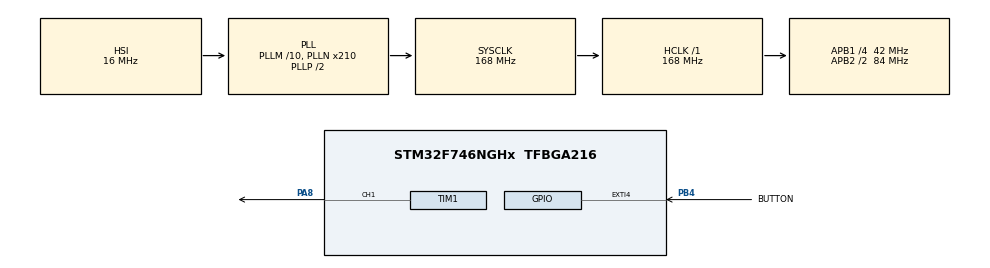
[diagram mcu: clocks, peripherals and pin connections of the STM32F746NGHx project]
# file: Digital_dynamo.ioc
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Mcu.Family=STM32F7
Mcu.Name=STM32F746NGHx
Mcu.Package=TFBGA216
NVIC.EXTI4_IRQn=true\:1\:0\:true\:false\:true\:true\:true
NVIC.PriorityGroup=NVIC_PRIORITYGROUP_4
NVIC.TIM8_TRG_COM_TIM14_IRQn=true\:0\:0\:false\:false\:true\:false\:true
NVIC.TimeBase=TIM8_TRG_COM_TIM14_IRQn
NVIC.TimeBaseIP=TIM14
PA13.Mode=Serial_Wire
PA13.Signal=SYS_JTMS-SWDIO
PA14.Mode=Serial_Wire
PA14.Signal=SYS_JTCK-SWCLK
PA8.Signal=S_TIM1_CH1
PB4.GPIO_Label=BUTTON
PB4.GPIO_PuPd=GPIO_PULLDOWN
PB4.Signal=GPXTI4
PC14/OSC32_IN.Mode=LSE-External-Clock-Source
PC14/OSC32_IN.Signal=RCC_OSC32_IN
PC15/OSC32_OUT.Mode=LSE-External-Clock-Source
PC15/OSC32_OUT.Signal=RCC_OSC32_OUT
PH0/OSC_IN.Mode=HSE-External-Oscillator
PH0/OSC_IN.Signal=RCC_OSC_IN
PH1/OSC_OUT.Mode=HSE-External-Oscillator
PH1/OSC_OUT.Signal=RCC_OSC_OUT
ProjectManager.HeapSize=0x200
ProjectManager.StackSize=0x400
ProjectManager.TargetToolchain=STM32CubeIDE
RCC.AHBFreq_Value=168000000
RCC.APB1CLKDivider=RCC_HCLK_DIV4
RCC.APB1Freq_Value=42000000
RCC.APB1TimFreq_Value=84000000
RCC.APB2CLKDivider=RCC_HCLK_DIV2
RCC.APB2Freq_Value=84000000
RCC.APB2TimFreq_Value=168000000
RCC.CortexFreq_Value=168000000
RCC.HCLKFreq_Value=168000000
RCC.HSE_VALUE=25000000
RCC.HSI_VALUE=16000000
RCC.LSE_VALUE=32768
RCC.PLLM=10
RCC.PLLN=210
RCC.PLLSourceVirtual=RCC_PLLSOURCE_HSI
RCC.SYSCLKFreq_VALUE=168000000
RCC.SYSCLKSource=RCC_SYSCLKSOURCE_PLLCLK
RCC.USBFreq_Value=168000000
RCC.VCOOutputFreq_Value=336000000
SH.S_TIM1_CH1.0=TIM1_CH1,PWM Generation1 CH1
TIM1.Channel-PWM\ Generation1\ CH1=TIM_CHANNEL_1
TIM1.Period=100
TIM1.Prescaler=168
VP_SYS_VS_tim14.Mode=TIM14
VP_TIM1_VS_ClockSourceINT.Mode=Internal
board=STM32F746G-DISCO

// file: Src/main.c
/* USER CODE BEGIN Header */
/**
  ******************************************************************************
  * @file           : main.c
  * @brief          : Main program body
  ******************************************************************************
  * @attention
  *
  * <h2><center>&copy; Copyright (c) 2019 STMicroelectronics.
  * All rights reserved.</center></h2>
  *
  * This software component is licensed by ST under BSD 3-Clause license,
  * the "License"; You may not use this file except in compliance with the
  * License. You may obtain a copy of the License at:
  *                        opensource.org/licenses/BSD-3-Clause
  *
  ******************************************************************************
  */
/* USER CODE END Header */

#include "main.h"

TIM_HandleTypeDef htim1;

/* USER CODE BEGIN PV */
int i = 100;

/* USER CODE END PV */

void SystemClock_Config(void);
static void MX_GPIO_Init(void);
static void MX_TIM1_Init(void);

int main(void)
{

  /* MCU Configuration--------------------------------------------------------*/

  /* Reset of all peripherals, Initializes the Flash interface and the Systick. */
  HAL_Init();

  /* Configure the system clock */
  SystemClock_Config();

  /* Initialize all configured peripherals */
  MX_GPIO_Init();
  MX_TIM1_Init();
  /* USER CODE BEGIN 2 */

  HAL_TIM_PWM_Start(&htim1, TIM_CHANNEL_1);

  /* USER CODE END 2 */

  /* Infinite loop */
  /* USER CODE BEGIN WHILE */
  while (1)
  {
	  while(i>0){
		  __HAL_TIM_SET_COMPARE(&htim1, TIM_CHANNEL_1, i);
	  	  		i--;
	  	  		HAL_Delay(20);
	  }

    /* USER CODE END WHILE */

  }
}

void SystemClock_Config(void)
{
  RCC_OscInitTypeDef RCC_OscInitStruct = {0};
  RCC_ClkInitTypeDef RCC_ClkInitStruct = {0};

  /** Configure the main internal regulator output voltage
  */
  __HAL_RCC_PWR_CLK_ENABLE();
  __HAL_PWR_VOLTAGESCALING_CONFIG(PWR_REGULATOR_VOLTAGE_SCALE2);
  /** Initializes the CPU, AHB and APB busses clocks
  */
  RCC_OscInitStruct.OscillatorType = RCC_OSCILLATORTYPE_HSI;
  RCC_OscInitStruct.HSIState = RCC_HSI_ON;
  RCC_OscInitStruct.HSICalibrationValue = RCC_HSICALIBRATION_DEFAULT;
  RCC_OscInitStruct.PLL.PLLState = RCC_PLL_ON;
  RCC_OscInitStruct.PLL.PLLSource = RCC_PLLSOURCE_HSI;
  RCC_OscInitStruct.PLL.PLLM = 10;
  RCC_OscInitStruct.PLL.PLLN = 210;
  RCC_OscInitStruct.PLL.PLLP = RCC_PLLP_DIV2;
  RCC_OscInitStruct.PLL.PLLQ = 2;
  if (HAL_RCC_OscConfig(&RCC_OscInitStruct) != HAL_OK)
  {
    Error_Handler();
  }
  /** Initializes the CPU, AHB and APB busses clocks
  */
  RCC_ClkInitStruct.ClockType = RCC_CLOCKTYPE_HCLK|RCC_CLOCKTYPE_SYSCLK
                              |RCC_CLOCKTYPE_PCLK1|RCC_CLOCKTYPE_PCLK2;
  RCC_ClkInitStruct.SYSCLKSource = RCC_SYSCLKSOURCE_PLLCLK;
  RCC_ClkInitStruct.AHBCLKDivider = RCC_SYSCLK_DIV1;
  RCC_ClkInitStruct.APB1CLKDivider = RCC_HCLK_DIV4;
  RCC_ClkInitStruct.APB2CLKDivider = RCC_HCLK_DIV2;

  if (HAL_RCC_ClockConfig(&RCC_ClkInitStruct, FLASH_LATENCY_5) != HAL_OK)
  {
    Error_Handler();
  }
}

static void MX_TIM1_Init(void)
{

  TIM_ClockConfigTypeDef sClockSourceConfig = {0};
  TIM_MasterConfigTypeDef sMasterConfig = {0};
  TIM_OC_InitTypeDef sConfigOC = {0};
  TIM_BreakDeadTimeConfigTypeDef sBreakDeadTimeConfig = {0};

  htim1.Instance = TIM1;
  htim1.Init.Prescaler = 168;
  htim1.Init.CounterMode = TIM_COUNTERMODE_UP;
  htim1.Init.Period = 100;
  htim1.Init.ClockDivision = TIM_CLOCKDIVISION_DIV1;
  htim1.Init.RepetitionCounter = 0;
  htim1.Init.AutoReloadPreload = TIM_AUTORELOAD_PRELOAD_DISABLE;
  if (HAL_TIM_Base_Init(&htim1) != HAL_OK)
  {
    Error_Handler();
  }
  sClockSourceConfig.ClockSource = TIM_CLOCKSOURCE_INTERNAL;
  if (HAL_TIM_ConfigClockSource(&htim1, &sClockSourceConfig) != HAL_OK)
  {
    Error_Handler();
  }
  if (HAL_TIM_PWM_Init(&htim1) != HAL_OK)
  {
    Error_Handler();
  }
  sMasterConfig.MasterOutputTrigger = TIM_TRGO_RESET;
  sMasterConfig.MasterOutputTrigger2 = TIM_TRGO2_RESET;
  sMasterConfig.MasterSlaveMode = TIM_MASTERSLAVEMODE_DISABLE;
  if (HAL_TIMEx_MasterConfigSynchronization(&htim1, &sMasterConfig) != HAL_OK)
  {
    Error_Handler();
  }
  sConfigOC.OCMode = TIM_OCMODE_PWM1;
  sConfigOC.Pulse = 0;
  sConfigOC.OCPolarity = TIM_OCPOLARITY_HIGH;
  sConfigOC.OCNPolarity = TIM_OCNPOLARITY_HIGH;
  sConfigOC.OCFastMode = TIM_OCFAST_DISABLE;
  sConfigOC.OCIdleState = TIM_OCIDLESTATE_RESET;
  sConfigOC.OCNIdleState = TIM_OCNIDLESTATE_RESET;
  if (HAL_TIM_PWM_ConfigChannel(&htim1, &sConfigOC, TIM_CHANNEL_1) != HAL_OK)
  {
    Error_Handler();
  }
  sBreakDeadTimeConfig.OffStateRunMode = TIM_OSSR_DISABLE;
  sBreakDeadTimeConfig.OffStateIDLEMode = TIM_OSSI_DISABLE;
  sBreakDeadTimeConfig.LockLevel = TIM_LOCKLEVEL_OFF;
  sBreakDeadTimeConfig.DeadTime = 0;
  sBreakDeadTimeConfig.BreakState = TIM_BREAK_DISABLE;
  sBreakDeadTimeConfig.BreakPolarity = TIM_BREAKPOLARITY_HIGH;
  sBreakDeadTimeConfig.BreakFilter = 0;
  sBreakDeadTimeConfig.Break2State = TIM_BREAK2_DISABLE;
  sBreakDeadTimeConfig.Break2Polarity = TIM_BREAK2POLARITY_HIGH;
  sBreakDeadTimeConfig.Break2Filter = 0;
  sBreakDeadTimeConfig.AutomaticOutput = TIM_AUTOMATICOUTPUT_DISABLE;
  if (HAL_TIMEx_ConfigBreakDeadTime(&htim1, &sBreakDeadTimeConfig) != HAL_OK)
  {
    Error_Handler();
  }
  HAL_TIM_MspPostInit(&htim1);

}

static void MX_GPIO_Init(void)
{
  GPIO_InitTypeDef GPIO_InitStruct = {0};

  /* GPIO Ports Clock Enable */
  __HAL_RCC_GPIOB_CLK_ENABLE();
  __HAL_RCC_GPIOA_CLK_ENABLE();
  __HAL_RCC_GPIOC_CLK_ENABLE();
  __HAL_RCC_GPIOH_CLK_ENABLE();

  /*Configure GPIO pin : BUTTON_Pin */
  GPIO_InitStruct.Pin = BUTTON_Pin;
  GPIO_InitStruct.Mode = GPIO_MODE_IT_RISING;
  GPIO_InitStruct.Pull = GPIO_PULLDOWN;
  HAL_GPIO_Init(BUTTON_GPIO_Port, &GPIO_InitStruct);

  /* EXTI interrupt init*/
  HAL_NVIC_SetPriority(EXTI4_IRQn, 1, 0);
  HAL_NVIC_EnableIRQ(EXTI4_IRQn);

}

/* USER CODE BEGIN 4 */
/*void EXTI15_10_IRQHandler(void)
{
    HAL_GPIO_EXTI_IRQHandler(BUTTON_Pin);
}*/

void HAL_GPIO_EXTI_Callback(uint16_t GPIO_Pin)
{
    i += 10;
}

/* USER CODE END 4 */

void HAL_TIM_PeriodElapsedCallback(TIM_HandleTypeDef *htim)
{
  if (htim->Instance == TIM14) {
    HAL_IncTick();
  }
}

void Error_Handler(void)
{
}

/************************ (C) COPYRIGHT STMicroelectronics *****END OF FILE****/
